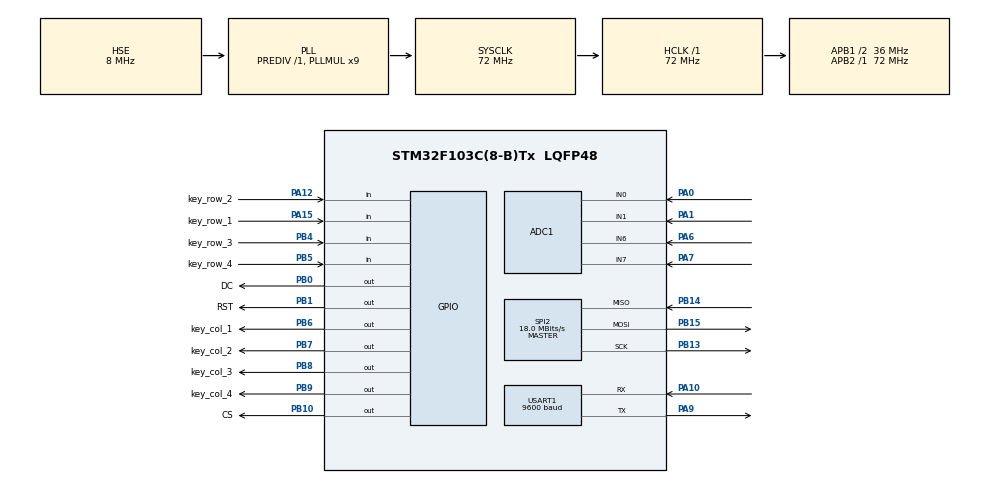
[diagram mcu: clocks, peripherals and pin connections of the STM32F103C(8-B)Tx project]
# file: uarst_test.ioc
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ADC1.Channel-4\#ChannelRegularConversion=ADC_CHANNEL_7
ADC1.Channel-5\#ChannelRegularConversion=ADC_CHANNEL_6
ADC1.Channel-6\#ChannelRegularConversion=ADC_CHANNEL_0
ADC1.Channel-7\#ChannelRegularConversion=ADC_CHANNEL_1
ADC1.ContinuousConvMode=ENABLE
ADC1.NbrOfConversion=4
ADC1.NbrOfConversionFlag=1
ADC1.Rank-4\#ChannelRegularConversion=1
ADC1.Rank-5\#ChannelRegularConversion=2
ADC1.Rank-6\#ChannelRegularConversion=3
ADC1.Rank-7\#ChannelRegularConversion=4
ADC1.SamplingTime-4\#ChannelRegularConversion=ADC_SAMPLETIME_239CYCLES_5
ADC1.SamplingTime-5\#ChannelRegularConversion=ADC_SAMPLETIME_239CYCLES_5
ADC1.SamplingTime-6\#ChannelRegularConversion=ADC_SAMPLETIME_239CYCLES_5
ADC1.SamplingTime-7\#ChannelRegularConversion=ADC_SAMPLETIME_239CYCLES_5
ADC1.master=1
Dma.ADC1.1.Direction=DMA_PERIPH_TO_MEMORY
Dma.ADC1.1.Instance=DMA1_Channel1
Dma.ADC1.1.MemDataAlignment=DMA_MDATAALIGN_WORD
Dma.ADC1.1.MemInc=DMA_MINC_ENABLE
Dma.ADC1.1.Mode=DMA_CIRCULAR
Dma.ADC1.1.PeriphDataAlignment=DMA_PDATAALIGN_WORD
Dma.ADC1.1.PeriphInc=DMA_PINC_DISABLE
Dma.ADC1.1.Priority=DMA_PRIORITY_LOW
Dma.Request0=USART1_TX
Dma.Request1=ADC1
Dma.USART1_TX.0.Direction=DMA_MEMORY_TO_PERIPH
Dma.USART1_TX.0.Instance=DMA1_Channel4
Dma.USART1_TX.0.MemDataAlignment=DMA_MDATAALIGN_BYTE
Dma.USART1_TX.0.MemInc=DMA_MINC_ENABLE
Dma.USART1_TX.0.Mode=DMA_NORMAL
Dma.USART1_TX.0.PeriphDataAlignment=DMA_PDATAALIGN_BYTE
Dma.USART1_TX.0.PeriphInc=DMA_PINC_DISABLE
Dma.USART1_TX.0.Priority=DMA_PRIORITY_LOW
FREERTOS.Tasks01=Task1,0,128,StartTask01,Default,NULL,Dynamic,NULL,NULL;Task2,-3,128,StartTask02,Default,NULL,Dynamic,NULL,NULL
Mcu.Family=STM32F1
Mcu.Name=STM32F103C(8-B)Tx
Mcu.Package=LQFP48
NVIC.ADC1_2_IRQn=true\:5\:0\:false\:false\:true\:true\:true\:true
NVIC.DMA1_Channel1_IRQn=true\:5\:0\:false\:false\:true\:true\:false\:true
NVIC.DMA1_Channel4_IRQn=true\:5\:0\:false\:false\:true\:true\:false\:true
NVIC.PriorityGroup=NVIC_PRIORITYGROUP_4
NVIC.TIM2_IRQn=true\:5\:0\:false\:false\:true\:true\:true\:true
NVIC.TIM4_IRQn=true\:15\:0\:false\:false\:true\:false\:false\:true
NVIC.TimeBase=TIM4_IRQn
NVIC.TimeBaseIP=TIM4
NVIC.USART1_IRQn=true\:5\:0\:false\:false\:true\:true\:true\:true
PA0-WKUP.Signal=ADCx_IN0
PA1.Signal=ADCx_IN1
PA10.Mode=Asynchronous
PA10.Signal=USART1_RX
PA12.GPIO_Label=key_row_2
PA12.GPIO_PuPd=GPIO_PULLUP
PA12.Signal=GPIO_Input
PA13.Mode=Serial_Wire
PA13.Signal=SYS_JTMS-SWDIO
PA14.Mode=Serial_Wire
PA14.Signal=SYS_JTCK-SWCLK
PA15.GPIO_Label=key_row_1
PA15.GPIO_PuPd=GPIO_PULLUP
PA15.Signal=GPIO_Input
PA6.Signal=ADCx_IN6
PA7.Signal=ADCx_IN7
PA9.Mode=Asynchronous
PA9.Signal=USART1_TX
PB0.GPIO_Label=DC
PB0.GPIO_Speed=GPIO_SPEED_FREQ_LOW
PB0.Signal=GPIO_Output
PB1.GPIO_Label=RST
PB1.Signal=GPIO_Output
PB10.GPIO_Label=CS
PB10.Signal=GPIO_Output
PB13.Mode=Full_Duplex_Master
PB13.Signal=SPI2_SCK
PB14.Mode=Full_Duplex_Master
PB14.Signal=SPI2_MISO
PB15.Mode=Full_Duplex_Master
PB15.Signal=SPI2_MOSI
PB4.GPIO_Label=key_row_3
PB4.GPIO_PuPd=GPIO_PULLUP
PB4.Signal=GPIO_Input
PB5.GPIO_Label=key_row_4
PB5.GPIO_PuPd=GPIO_PULLUP
PB5.Signal=GPIO_Input
PB6.GPIO_Label=key_col_1
PB6.GPIO_PuPd=GPIO_NOPULL
PB6.PinState=GPIO_PIN_SET
PB6.Signal=GPIO_Output
PB7.GPIO_Label=key_col_2
PB7.GPIO_PuPd=GPIO_NOPULL
PB7.PinState=GPIO_PIN_SET
PB7.Signal=GPIO_Output
PB8.GPIO_Label=key_col_3
PB8.GPIO_PuPd=GPIO_NOPULL
PB8.PinState=GPIO_PIN_SET
PB8.Signal=GPIO_Output
PB9.GPIO_Label=key_col_4
PB9.GPIO_PuPd=GPIO_NOPULL
PB9.PinState=GPIO_PIN_SET
PB9.Signal=GPIO_Output
PD0-OSC_IN.Mode=HSE-External-Oscillator
PD0-OSC_IN.Signal=RCC_OSC_IN
PD1-OSC_OUT.Mode=HSE-External-Oscillator
PD1-OSC_OUT.Signal=RCC_OSC_OUT
ProjectManager.HeapSize=0x200
ProjectManager.StackSize=0x400
ProjectManager.TargetToolchain=MDK-ARM V5
RCC.ADCPresc=RCC_ADCPCLK2_DIV6
RCC.AHBFreq_Value=72000000
RCC.APB1CLKDivider=RCC_HCLK_DIV2
RCC.APB1Freq_Value=36000000
RCC.APB1TimFreq_Value=72000000
RCC.APB2Freq_Value=72000000
RCC.APB2TimFreq_Value=72000000
RCC.HCLKFreq_Value=72000000
RCC.PLLMUL=RCC_PLL_MUL9
RCC.PLLSourceVirtual=RCC_PLLSOURCE_HSE
RCC.SYSCLKFreq_VALUE=72000000
RCC.SYSCLKSource=RCC_SYSCLKSOURCE_PLLCLK
RCC.USBFreq_Value=72000000
SH.ADCx_IN0.0=ADC1_IN0,IN0
SH.ADCx_IN1.0=ADC1_IN1,IN1
SH.ADCx_IN6.0=ADC1_IN6,IN6
SH.ADCx_IN7.0=ADC1_IN7,IN7
SPI2.BaudRatePrescaler=SPI_BAUDRATEPRESCALER_2
SPI2.CalculateBaudRate=18.0 MBits/s
SPI2.Direction=SPI_DIRECTION_2LINES
SPI2.Mode=SPI_MODE_MASTER
SPI2.VirtualType=VM_MASTER
TIM2.Period=999
TIM2.Prescaler=7199
USART1.BaudRate=9600
USART1.VirtualMode=VM_ASYNC
VP_FREERTOS_VS_CMSIS_V1.Mode=CMSIS_V1
VP_SYS_VS_tim4.Mode=TIM4
VP_TIM2_VS_ClockSourceINT.Mode=Internal
board=custom

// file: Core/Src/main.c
/* USER CODE BEGIN Header */
/**
  ******************************************************************************
  * @file           : main.c
  * @brief          : Main program body
  ******************************************************************************
  * @attention
  *
  * <h2><center>&copy; Copyright (c) 2021 STMicroelectronics.
  * All rights reserved.</center></h2>
  *
  * This software component is licensed by ST under BSD 3-Clause license,
  * the "License"; You may not use this file except in compliance with the
  * License. You may obtain a copy of the License at:
  *                        opensource.org/licenses/BSD-3-Clause
  *
  ******************************************************************************
  */
/* USER CODE END Header */
#include "main.h"
#include "cmsis_os.h"
#include "adc.h"
#include "dma.h"
#include "spi.h"
#include "tim.h"
#include "usart.h"
#include "gpio.h"

/* USER CODE BEGIN Includes */
#include "ST7735.h"
#include "my_serial.h"
#include "app.h"
/* USER CODE END Includes */

/* USER CODE BEGIN PD */
// #define frequency 100
/* USER CODE END PD */

/* USER CODE BEGIN PV */
// uint32_t JOY_VALUE[4];
// float JOY_ADC_VALUE[4];
// uint8_t key;

/* USER CODE END PV */

void SystemClock_Config(void);
void MX_FREERTOS_Init(void);

/* USER CODE BEGIN 0 */
// void joy_decode(void){
//             if(JOY_VALUE[0] <= 2950)  JOY_ADC_VALUE[0] = (float)(JOY_VALUE[0]) / 5900;
//       else   JOY_ADC_VALUE[0] = ((float)JOY_VALUE[0] - 2950) / (1146*2)+0.5;
//             if(JOY_VALUE[1] <= 2950)  JOY_ADC_VALUE[1] = (float)(JOY_VALUE[1]) / 5900;
//       else   JOY_ADC_VALUE[1] = ((float)JOY_VALUE[1] - 2950) / (1146*2)+0.5;
//             if(JOY_VALUE[2] <= 2950)  JOY_ADC_VALUE[2] = (float)(JOY_VALUE[2]) / 5900;
//       else   JOY_ADC_VALUE[2] = ((float)JOY_VALUE[2] - 2950) / (1146*2)+0.5;
//             if(JOY_VALUE[3] <= 2950)  JOY_ADC_VALUE[3] = (float)(JOY_VALUE[3]) / 5900;
//       else   JOY_ADC_VALUE[3] = ((float)JOY_VALUE[3] - 2950) / (1146*2)+0.5;
// }

/* USER CODE END 0 */

int main(void)
{

  /* MCU Configuration--------------------------------------------------------*/

  /* Reset of all peripherals, Initializes the Flash interface and the Systick. */
  HAL_Init();

  /* Configure the system clock */
  SystemClock_Config();

  /* Initialize all configured peripherals */
  MX_GPIO_Init();
  MX_DMA_Init();
  MX_USART1_UART_Init();
  MX_ADC1_Init();
  MX_SPI2_Init();
  MX_TIM2_Init();
  /* USER CODE BEGIN 2 */

//  HAL_ADC_Start_DMA(&hadc1, JOY_VALUE, 4);
  /* USER CODE END 2 */

  /* Call init function for freertos objects (in freertos.c) */
  MX_FREERTOS_Init();
  /* Start scheduler */
  osKernelStart();

  /* We should never get here as control is now taken by the scheduler */
  /* Infinite loop */
  while (1)
  {

    /* USER CODE BEGIN 3 */
// static int cnt = 1000/frequency;

// if(cnt--<0)
// {
//   code();

//   if(HAL_UART_Transmit_DMA(&huart1,(uint8_t*)sendbag.raw,BAG_LENGTH)==HAL_OK) flag++;

//   else  {
//     Error_Handler();
//   }

//   cnt = 1000/frequency;
// }

        //摇杆读取处理
       //joy_decode();

        //矩阵键盘读取处理
       // key = key_scan();

        //显示�??
        //display();

       // HAL_Delay(1);
  }
  /* USER CODE END 3 */
}

void SystemClock_Config(void)
{
  RCC_OscInitTypeDef RCC_OscInitStruct = {0};
  RCC_ClkInitTypeDef RCC_ClkInitStruct = {0};
  RCC_PeriphCLKInitTypeDef PeriphClkInit = {0};

  /** Initializes the RCC Oscillators according to the specified parameters
  * in the RCC_OscInitTypeDef structure.
  */
  RCC_OscInitStruct.OscillatorType = RCC_OSCILLATORTYPE_HSE;
  RCC_OscInitStruct.HSEState = RCC_HSE_ON;
  RCC_OscInitStruct.HSEPredivValue = RCC_HSE_PREDIV_DIV1;
  RCC_OscInitStruct.HSIState = RCC_HSI_ON;
  RCC_OscInitStruct.PLL.PLLState = RCC_PLL_ON;
  RCC_OscInitStruct.PLL.PLLSource = RCC_PLLSOURCE_HSE;
  RCC_OscInitStruct.PLL.PLLMUL = RCC_PLL_MUL9;
  if (HAL_RCC_OscConfig(&RCC_OscInitStruct) != HAL_OK)
  {
    Error_Handler();
  }
  /** Initializes the CPU, AHB and APB buses clocks
  */
  RCC_ClkInitStruct.ClockType = RCC_CLOCKTYPE_HCLK|RCC_CLOCKTYPE_SYSCLK
                              |RCC_CLOCKTYPE_PCLK1|RCC_CLOCKTYPE_PCLK2;
  RCC_ClkInitStruct.SYSCLKSource = RCC_SYSCLKSOURCE_PLLCLK;
  RCC_ClkInitStruct.AHBCLKDivider = RCC_SYSCLK_DIV1;
  RCC_ClkInitStruct.APB1CLKDivider = RCC_HCLK_DIV2;
  RCC_ClkInitStruct.APB2CLKDivider = RCC_HCLK_DIV1;

  if (HAL_RCC_ClockConfig(&RCC_ClkInitStruct, FLASH_LATENCY_2) != HAL_OK)
  {
    Error_Handler();
  }
  PeriphClkInit.PeriphClockSelection = RCC_PERIPHCLK_ADC;
  PeriphClkInit.AdcClockSelection = RCC_ADCPCLK2_DIV6;
  if (HAL_RCCEx_PeriphCLKConfig(&PeriphClkInit) != HAL_OK)
  {
    Error_Handler();
  }
}

void Error_Handler(void)
{
  __disable_irq();
  while (1)
  {
  }
}

/************************ (C) COPYRIGHT STMicroelectronics *****END OF FILE****/

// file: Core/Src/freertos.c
/* USER CODE BEGIN Header */
/**
  ******************************************************************************
  * File Name          : freertos.c
  * Description        : Code for freertos applications
  ******************************************************************************
  * @attention
  *
  * <h2><center>&copy; Copyright (c) 2021 STMicroelectronics.
  * All rights reserved.</center></h2>
  *
  * This software component is licensed by ST under Ultimate Liberty license
  * SLA0044, the "License"; You may not use this file except in compliance with
  * the License. You may obtain a copy of the License at:
  *                             www.st.com/SLA0044
  *
  ******************************************************************************
  */
/* USER CODE END Header */

#include "FreeRTOS.h"
#include "task.h"
#include "main.h"
#include "cmsis_os.h"
#include "ST7735.h"
#include "my_serial.h"
#include "app.h"
#include "adc.h"
#include "dma.h"
#include "spi.h"
#include "tim.h"
#include "usart.h"
#include "gpio.h"

osThreadId Task1Handle;
osThreadId Task2Handle;

void StartTask01(void const * argument);
void StartTask02(void const * argument);

void MX_FREERTOS_Init(void); /* (MISRA C 2004 rule 8.1) */

/* GetIdleTaskMemory prototype (linked to static allocation support) */
void vApplicationGetIdleTaskMemory( StaticTask_t **ppxIdleTaskTCBBuffer, StackType_t **ppxIdleTaskStackBuffer, uint32_t *pulIdleTaskStackSize );

/* USER CODE BEGIN GET_IDLE_TASK_MEMORY */
static StaticTask_t xIdleTaskTCBBuffer;
static StackType_t xIdleStack[configMINIMAL_STACK_SIZE];

void vApplicationGetIdleTaskMemory( StaticTask_t **ppxIdleTaskTCBBuffer, StackType_t **ppxIdleTaskStackBuffer, uint32_t *pulIdleTaskStackSize )
{
  *ppxIdleTaskTCBBuffer = &xIdleTaskTCBBuffer;
  *ppxIdleTaskStackBuffer = &xIdleStack[0];
  *pulIdleTaskStackSize = configMINIMAL_STACK_SIZE;
  /* place for user code */
}
/* USER CODE END GET_IDLE_TASK_MEMORY */

void MX_FREERTOS_Init(void) {

  /* Create the thread(s) */
  /* definition and creation of Task1 */
  osThreadDef(Task1, StartTask01, osPriorityNormal, 0, 128);
  Task1Handle = osThreadCreate(osThread(Task1), NULL);

  /* definition and creation of Task2 */
  osThreadDef(Task2, StartTask02, osPriorityIdle, 0, 128);
  Task2Handle = osThreadCreate(osThread(Task2), NULL);

  /* USER CODE BEGIN RTOS_THREADS */
  start_init();
  /* add threads, ... */
  /* USER CODE END RTOS_THREADS */

}

void StartTask01(void const * argument)
{
  /* USER CODE BEGIN StartTask01 */
  /* Infinite loop */
  for(;;)
  {
    joy_decode();
    key = key_scan();
    vTaskDelay(1);
  }
  /* USER CODE END StartTask01 */
}

void StartTask02(void const * argument)
{
  /* USER CODE BEGIN StartTask02 */
  /* Infinite loop */
  for(;;)
  {
    display();
    vTaskDelay(1);
  }
  /* USER CODE END StartTask02 */
}

/************************ (C) COPYRIGHT STMicroelectronics *****END OF FILE****/
